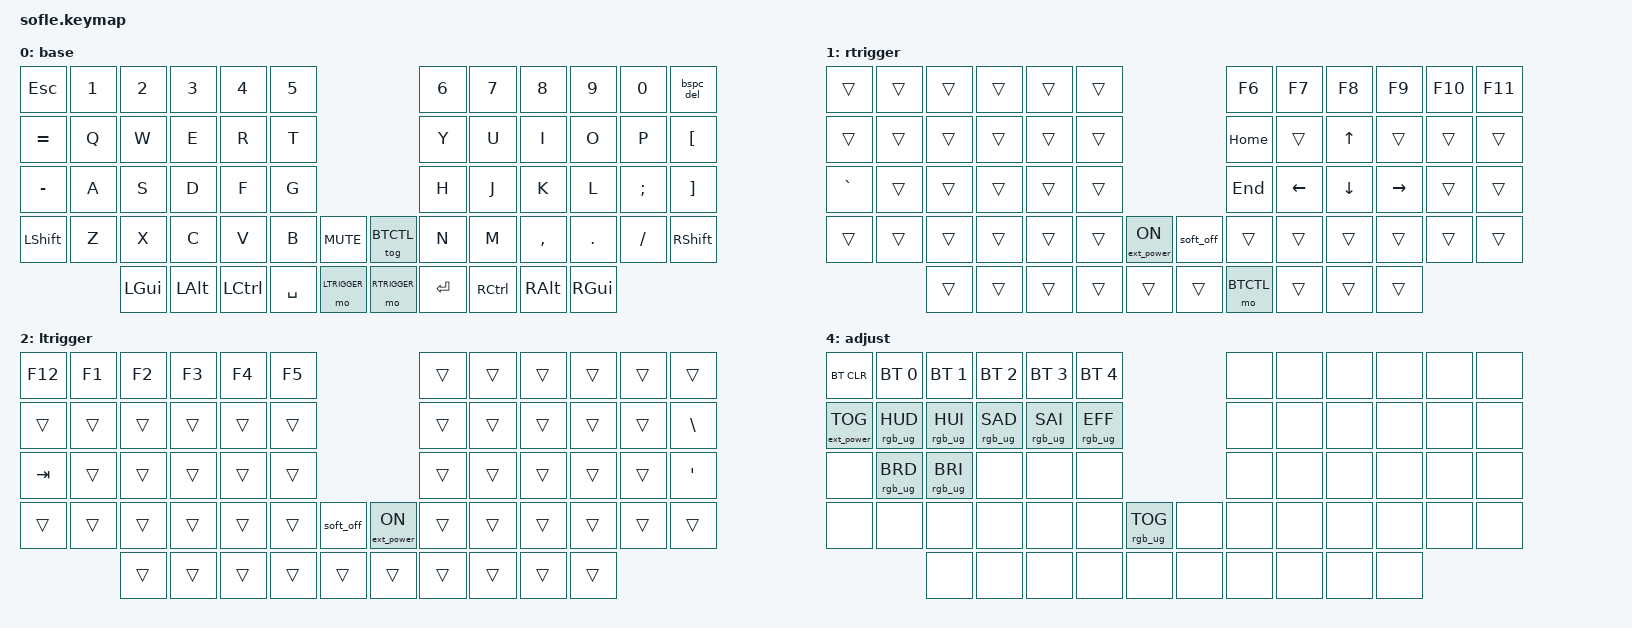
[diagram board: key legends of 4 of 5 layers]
/*
 * Copyright (c) 2020 The ZMK Contributors
 *
 * SPDX-License-Identifier: MIT
 */

#include <behaviors.dtsi>
#include <dt-bindings/zmk/keys.h>
#include <dt-bindings/zmk/bt.h>
#include <dt-bindings/zmk/rgb.h>
#include <dt-bindings/zmk/ext_power.h>
#include <dt-bindings/zmk/outputs.h>

#define BASE 0
#define RTRIGGER 1
#define LTRIGGER 2
#define BTCTL 3

/ {

    behaviors {
        bspc_del: backspace_delete {
            compatible = "zmk,behavior-mod-morph";
            #binding-cells = <0>;
            bindings = <&kp BSPC>, <&kp DEL>;
            mods = <(MOD_LSFT|MOD_RSFT)>;
        };
    };

    // | 00 | 01 | 02 | 03 | 04 | 05 |          | 06 | 07 | 08 | 09 | 10 | 11 |
    // | 12 | 13 | 14 | 15 | 16 | 17 |          | 18 | 19 | 20 | 21 | 22 | 23 |
    // | 24 | 25 | 26 | 27 | 28 | 29 |          | 30 | 31 | 32 | 33 | 34 | 35 |
    // | 36 | 37 | 38 | 39 | 40 | 41 | 42 || 43 | 44 | 45 | 46 | 47 | 48 | 49 |
    //     | 50 | 51 | 52 | 53 | 54 |            | 55 | 56 | 57 | 58 | 59 |

    combos {
        compatible = "zmk,combos";
        combo_caps {
            timeout-ms = <50>;
            key-positions = <36 49>;
            bindings = <&kp CAPS>;
        };

        combo_left_tab {
            timeout-ms = <30>;
            key-positions = <24 25>;
            bindings = <&kp TAB>;
        };
        combo_right_tab {
            timeout-ms = <30>;
            key-positions = <34 35>;
            bindings = <&kp TAB>;
        };

        combo_left_caps {
            timeout-ms = <30>;
            key-positions = <36 37>;
            bindings = <&kp CAPS>;
        };
        combo_right_caps {
            timeout-ms = <30>;
            key-positions = <48 49>;
            bindings = <&kp CAPS>;
        };

        combo_bt_ctrl {
            timeout-ms = <50>;
            key-positions = <53 54>;
            bindings = <&tog BTCTL>;
        };
        combo_left_shutdown {
            timeout-ms = <50>;
            key-positions = <25 29>;
            bindings = <&soft_off>;
        };
        combo_right_shutdown {
            timeout-ms = <50>;
            key-positions = <30 34>;
            bindings = <&soft_off>;
        };
    };

    keymap {
        compatible = "zmk,keymap";

        default_layer {
            display-name = "base";

    // | X | X | X | X | X | X |        | X | X | X | X | X | X |
    // | X | X | X | X | X | X |        | X | X | X | X | X | X |
    // | X | X | X | X | X | X |        | X | X | X | X | X | X |
    // | X | X | X | X | X | X | O || O | X | X | X | X | X | X |
    //     | X | X | X | X | X |        | X | X | X | X | X |

            bindings = <
&kp ESC &kp N1 &kp N2 &kp N3 &kp N4 &kp N5  &kp N6 &kp N7 &kp N8 &kp N9 &kp N0 &bspc_del
&kp EQUAL &kp Q &kp W &kp E &kp R &kp T  &kp Y &kp U &kp I &kp O &kp P &kp LBKT
&kp MINUS &kp A &kp S &kp D &kp F &kp G  &kp H &kp J &kp K &kp L &kp SEMI &kp RBKT
&kp LSHFT &kp Z &kp X &kp C &kp V &kp B &kp C_MUTE  &tog BTCTL &kp N &kp M &kp COMMA &kp DOT &kp FSLH &kp RSHFT
&kp LGUI &kp LALT &kp LCTRL &kp SPACE &mo LTRIGGER    &mo RTRIGGER &kp RET &kp RCTRL &kp RALT &kp RGUI
            >;

            sensor-bindings = <&inc_dec_kp C_VOL_UP C_VOL_DN &inc_dec_kp PG_UP PG_DN>;
        };

        rtrigger_layer {
            display-name = "rtrigger";
            bindings = <
&trans &trans &trans &trans &trans &trans  &kp F6 &kp F7 &kp F8 &kp F9 &kp F10 &kp F11
&trans &trans &trans &trans &trans &trans  &kp HOME &trans &kp UP &trans &trans &trans
&kp GRAVE &trans &trans &trans &trans &trans  &kp END &kp LEFT &kp DOWN &kp RIGHT &trans &trans
&trans &trans &trans &trans &trans &trans &ext_power EP_ON  &soft_off &trans &trans &trans &trans &trans &trans
&trans &trans &trans &trans &trans  &trans &mo BTCTL &trans &trans &trans
            >;

            sensor-bindings = <&inc_dec_kp C_VOL_UP C_VOL_DN &inc_dec_kp PG_UP PG_DN>;
        };

        ltrigger_layer {
            display-name = "ltrigger";
            bindings = <
&kp F12 &kp F1 &kp F2 &kp F3 &kp F4 &kp F5  &trans &trans &trans &trans &trans &trans
&trans &trans &trans &trans &trans &trans  &trans &trans &trans &trans &trans &kp BSLH
&kp TAB &trans &trans &trans &trans &trans  &trans &trans &trans &trans &trans &kp SQT
&trans &trans &trans &trans &trans &trans &soft_off  &ext_power EP_ON &trans &trans &trans &trans &trans &trans
&trans &trans &trans &trans &trans  &trans &trans &trans &trans &trans
            >;

            sensor-bindings = <&inc_dec_kp C_VOL_UP C_VOL_DN &inc_dec_kp PG_UP PG_DN>;
        };

        btctl {
            display-name = "btctl";
            bindings = <
&bt BT_CLR &bt BT_SEL 0 &bt BT_SEL 1 &bt BT_SEL 2 &bt BT_SEL 3 &bt BT_SEL 4  &none &none &none &none &none &none
&bt BT_NXT &none &none &none &none &none  &none &none &none &none &none &none
&bt BT_PRV &none &none &none &none &none  &none &none &none &none &none &none
&none &none &none &none &none &none &out OUT_BLE  &tog BTCTL &none &none &none &none &none &none
&none &none &none &none &none  &none &none &none &none &none &none
            >;

            sensor-bindings = <&inc_dec_kp C_VOL_UP C_VOL_DN &inc_dec_kp PG_UP PG_DN>;
        };

        adjust_layer {
// ----------------------------------------------------------------------------------------------------------------------------
// | BTCLR  |  BT1    |  BT2    |   BT3   |   BT4   |   BT5   |                  |      |      |       |      |       |       |
// | EXTPWR | RGB_HUD | RGB_HUI | RGB_SAD | RGB_SAI | RGB_EFF |                  |      |      |       |      |       |       |
// |        | RGB_BRD | RGB_BRI |         |         |         |                  |      |      |       |      |       |       |
// |        |         |         |         |         |         | RGB_TOG | |      |      |      |       |      |       |       |
//                    |         |         |         |         |         | |      |      |      |       |      |
            display-name = "adjust";
            bindings = <
&bt BT_CLR        &bt BT_SEL 0    &bt BT_SEL 1    &bt BT_SEL 2    &bt BT_SEL 3    &bt BT_SEL 4                            &none &none &none &none &none &none
&ext_power EP_TOG &rgb_ug RGB_HUD &rgb_ug RGB_HUI &rgb_ug RGB_SAD &rgb_ug RGB_SAI &rgb_ug RGB_EFF                         &none &none &none &none &none &none
&none             &rgb_ug RGB_BRD &rgb_ug RGB_BRI &none           &none           &none                                   &none &none &none &none &none &none
&none             &none           &none           &none           &none           &none            &rgb_ug RGB_TOG &none  &none &none &none &none &none &none
                                  &none           &none           &none           &none            &none           &none  &none &none &none &none
            >;
        };

    };
};
